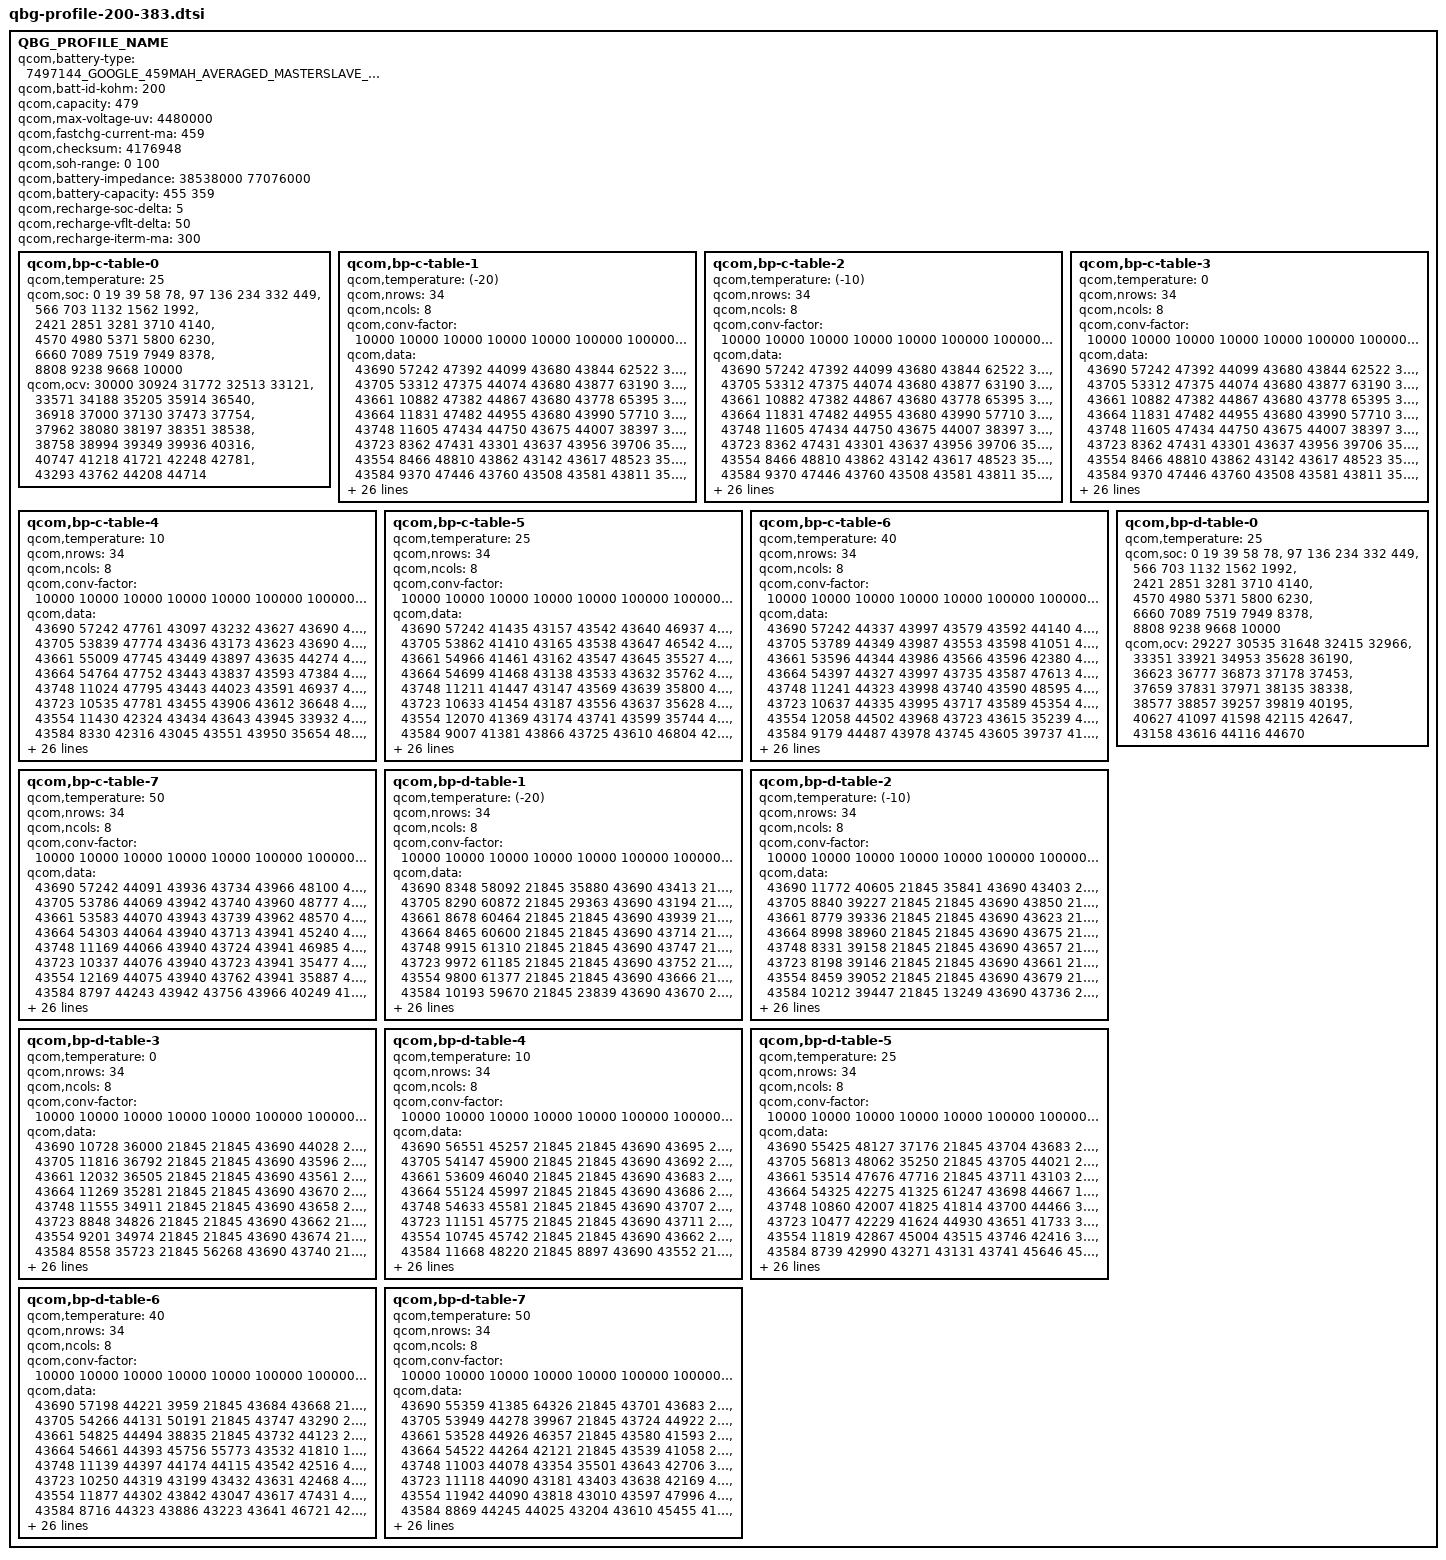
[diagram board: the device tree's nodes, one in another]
/*QBG Profiling Rev. 2.8*/

QBG_PROFILE_NAME {
	qcom,battery-type = "7497144_GOOGLE_459MAH_AVERAGED_MASTERSLAVE_DEC2ND2024";
	qcom,batt-id-kohm = <200>;
	qcom,capacity = <479>;
	qcom,max-voltage-uv = <4480000>;
	qcom,fastchg-current-ma = <459>;
	qcom,checksum = <4176948>; /*@5, 0.005V, 4% */
	qcom,soh-range = <0 100>;
	qcom,battery-impedance = <38538000 77076000>; /*Nominal_Impedance in 10nohm @ SOC 50% 25C* 0:fresh cell, 1: aged cell*/
	qcom,battery-capacity = <455 359>; /*Nominal_Capacity in mAh. 0: fresh cell, 1:aged cell*/
	qcom,recharge-soc-delta =<5>; /*SOC delta (in percent) dropped from EOC SOC to enable recharge*/
	qcom,recharge-vflt-delta =<50>; /*vfloat delta (in mV) dropped from regular vfloat in recharge*/
	qcom,recharge-iterm-ma = <300>; /*termination current (in mA) in recharge*/

	qcom,bp-c-table-0 {
		qcom,temperature = <25>;
		qcom,soc = <    0    19    39    58    78>,
			<   97   136   234   332   449>,
			<  566   703  1132  1562  1992>,
			< 2421  2851  3281  3710  4140>,
			< 4570  4980  5371  5800  6230>,
			< 6660  7089  7519  7949  8378>,
			< 8808  9238  9668 10000>;
		qcom,ocv = <30000 30924 31772 32513 33121>,
			<33571 34188 35205 35914 36540>,
			<36918 37000 37130 37473 37754>,
			<37962 38080 38197 38351 38538>,
			<38758 38994 39349 39936 40316>,
			<40747 41218 41721 42248 42781>,
			<43293 43762 44208 44714>;
	};
	qcom,bp-c-table-1 {
		qcom,temperature = <(-20)>;
		qcom,nrows = <34>;
		qcom,ncols = <8>;
		qcom,conv-factor = <10000 10000 10000 10000 10000 100000 100000 10000>;
		qcom,data = <43690 57242 47392 44099 43680 43844 62522 35052>,
			<43705 53312 47375 44074 43680 43877 63190 34980>,
			<43661 10882 47382 44867 43680 43778 65395 35705>,
			<43664 11831 47482 44955 43680 43990 57710 35634>,
			<43748 11605 47434 44750 43675 44007 38397 35831>,
			<43723  8362 47431 43301 43637 43956 39706 35721>,
			<43554  8466 48810 43862 43142 43617 48523 35347>,
			<43584  9370 47446 43760 43508 43581 43811 35513>,
			<44006  9599 47478 43653 43510 43538 43969 46338>,
			<43883 14906 47480 43679 43415 43536 43997 46480>,
			<43164 14957 47389 43669 43499 43539 43984 46517>,
			<43029 14932 47462 43653 43412 43543 43818 46521>,
			<44742 14514 47470 43558 43469 43538 43799 46539>,
			<44208 14840 48810 44821 43941 43640 33210 34988>,
			<44386 16112 47470 44255 44031 43628 36693 35012>,
			<41951 15937 47570 44115 43800 43626 35830 34878>,
			<41353 16356 47569 44439 43843 43542 46591 35239>,
			<42619 16157 47417 44346 43148 43548 46959 35187>,
			<42196 15507 47486 44382 43204 43525 47082 36470>,
			<47750 15432 48825 41724 43063 43523 46945 36724>,
			<47984 15730 48873 41527 43016 43534 46951 35871>,
			<47582 13190 48667 41570 43216 43574 48158 36315>,
			<48721 12335 49053 41898 43049 43583 48003 33493>,
			<48130 13999 48993 41975 43026 43558 42968 32951>,
			<45820 14130 48345 41852 43439 43566 41432 34493>,
			<45230 13805 48548 41089 43473 43732 41924 33938>,
			<45339  3000 48409 41180 44691 43728 44341 39449>,
			<47093  2143 45596 40988 45003 43731 44261 40612>,
			<46503  3673 45831 40991 44542 43729 44648 37624>,
			<35344  3153 45065 41084 41115 43733 43343 38050>,
			<35010   597 45420 41028 41995 43563 43444 60587>,
			<36540   122 46792 41062 48595 43560 43068 63888>,
			<36718  1536 46691 41186 45332 43579 43178 63108>,
			<36282  1213 46216 43569 45746 43675 43529 65049>;
	};
	qcom,bp-c-table-2 {
		qcom,temperature = <(-10)>;
		qcom,nrows = <34>;
		qcom,ncols = <8>;
		qcom,conv-factor = <10000 10000 10000 10000 10000 100000 100000 10000>;
		qcom,data = <43690 57242 47392 44099 43680 43844 62522 35052>,
			<43705 53312 47375 44074 43680 43877 63190 34980>,
			<43661 10882 47382 44867 43680 43778 65395 35705>,
			<43664 11831 47482 44955 43680 43990 57710 35634>,
			<43748 11605 47434 44750 43675 44007 38397 35831>,
			<43723  8362 47431 43301 43637 43956 39706 35721>,
			<43554  8466 48810 43862 43142 43617 48523 35347>,
			<43584  9370 47446 43760 43508 43581 43811 35513>,
			<44006  9599 47478 43653 43510 43538 43969 46338>,
			<43883 14906 47480 43679 43415 43536 43997 46480>,
			<43164 14957 47389 43669 43499 43539 43984 46517>,
			<43029 14932 47462 43653 43412 43543 43818 46521>,
			<44742 14514 47470 43558 43469 43538 43799 46539>,
			<44208 14840 48810 44821 43941 43640 33210 34988>,
			<44386 16112 47470 44255 44031 43628 36693 35012>,
			<41951 15937 47570 44115 43800 43626 35830 34878>,
			<41353 16356 47569 44439 43843 43542 46591 35239>,
			<42619 16157 47417 44346 43148 43548 46959 35187>,
			<42196 15507 47486 44382 43204 43525 47082 36470>,
			<47750 15432 48825 41724 43063 43523 46945 36724>,
			<47984 15730 48873 41527 43016 43534 46951 35871>,
			<47582 13190 48667 41570 43216 43574 48158 36315>,
			<48721 12335 49053 41898 43049 43583 48003 33493>,
			<48130 13999 48993 41975 43026 43558 42968 32951>,
			<45820 14130 48345 41852 43439 43566 41432 34493>,
			<45230 13805 48548 41089 43473 43732 41924 33938>,
			<45339  3000 48409 41180 44691 43728 44341 39449>,
			<47093  2143 45596 40988 45003 43731 44261 40612>,
			<46503  3673 45831 40991 44542 43729 44648 37624>,
			<35344  3153 45065 41084 41115 43733 43343 38050>,
			<35010   597 45420 41028 41995 43563 43444 60587>,
			<36540   122 46792 41062 48595 43560 43068 63888>,
			<36718  1536 46691 41186 45332 43579 43178 63108>,
			<36282  1213 46216 43569 45746 43675 43529 65049>;
	};
	qcom,bp-c-table-3 {
		qcom,temperature = <0>;
		qcom,nrows = <34>;
		qcom,ncols = <8>;
		qcom,conv-factor = <10000 10000 10000 10000 10000 100000 100000 10000>;
		qcom,data = <43690 57242 47392 44099 43680 43844 62522 35052>,
			<43705 53312 47375 44074 43680 43877 63190 34980>,
			<43661 10882 47382 44867 43680 43778 65395 35705>,
			<43664 11831 47482 44955 43680 43990 57710 35634>,
			<43748 11605 47434 44750 43675 44007 38397 35831>,
			<43723  8362 47431 43301 43637 43956 39706 35721>,
			<43554  8466 48810 43862 43142 43617 48523 35347>,
			<43584  9370 47446 43760 43508 43581 43811 35513>,
			<44006  9599 47478 43653 43510 43538 43969 46338>,
			<43883 14906 47480 43679 43415 43536 43997 46480>,
			<43164 14957 47389 43669 43499 43539 43984 46517>,
			<43029 14932 47462 43653 43412 43543 43818 46521>,
			<44742 14514 47470 43558 43469 43538 43799 46539>,
			<44208 14840 48810 44821 43941 43640 33210 34988>,
			<44386 16112 47470 44255 44031 43628 36693 35012>,
			<41951 15937 47570 44115 43800 43626 35830 34878>,
			<41353 16356 47569 44439 43843 43542 46591 35239>,
			<42619 16157 47417 44346 43148 43548 46959 35187>,
			<42196 15507 47486 44382 43204 43525 47082 36470>,
			<47750 15432 48825 41724 43063 43523 46945 36724>,
			<47984 15730 48873 41527 43016 43534 46951 35871>,
			<47582 13190 48667 41570 43216 43574 48158 36315>,
			<48721 12335 49053 41898 43049 43583 48003 33493>,
			<48130 13999 48993 41975 43026 43558 42968 32951>,
			<45820 14130 48345 41852 43439 43566 41432 34493>,
			<45230 13805 48548 41089 43473 43732 41924 33938>,
			<45339  3000 48409 41180 44691 43728 44341 39449>,
			<47093  2143 45596 40988 45003 43731 44261 40612>,
			<46503  3673 45831 40991 44542 43729 44648 37624>,
			<35344  3153 45065 41084 41115 43733 43343 38050>,
			<35010   597 45420 41028 41995 43563 43444 60587>,
			<36540   122 46792 41062 48595 43560 43068 63888>,
			<36718  1536 46691 41186 45332 43579 43178 63108>,
			<36282  1213 46216 43569 45746 43675 43529 65049>;
	};
	qcom,bp-c-table-4 {
		qcom,temperature = <10>;
		qcom,nrows = <34>;
		qcom,ncols = <8>;
		qcom,conv-factor = <10000 10000 10000 10000 10000 100000 100000 10000>;
		qcom,data = <43690 57242 47761 43097 43232 43627 43690 45102>,
			<43705 53839 47774 43436 43173 43623 43690 45185>,
			<43661 55009 47745 43449 43897 43635 44274 45944>,
			<43664 54764 47752 43443 43837 43593 47384 46035>,
			<43748 11024 47795 43443 44023 43591 46937 45963>,
			<43723 10535 47781 43455 43906 43612 36648 45671>,
			<43554 11430 42324 43434 43643 43945 33932 45721>,
			<43584  8330 42316 43045 43551 43950 35654 48540>,
			<44006  9798 42363 43196 43602 43605 41573 48158>,
			<43883  9719 42271 43576 43241 43979 43112 48361>,
			<43164 15068 42297 43747 43044 43821 43991 48979>,
			<43029 14876 42278 43669 43062 43812 43996 49019>,
			<44742 15359 42445 43096 43577 43943 33431 48354>,
			<44208 14353 42424 44770 43595 43616 36732 48539>,
			<44386 14713 42093 44598 43957 43630 35969 48529>,
			<41951 15926 42192 44659 43921 43541 35311 48566>,
			<41353 16299 42216 44633 44031 43540 35627 48568>,
			<42619 16324 42151 44967 43993 43537 46288 48559>,
			<42196 16223 42147 44979 43813 43536 45368 48573>,
			<47750 15410 42843 44934 43801 43539 46639 48541>,
			<47984 15867 42826 45054 43903 43536 36316 48578>,
			<47582 12841 42865 45049 43777 43537 32848 48542>,
			<48721 12532 42878 44929 43922 43539 47036 48188>,
			<48130 13997 42825 45042 43924 43546 48859 48244>,
			<45820 14128 42123 44816 43999 43529 48055 48506>,
			<45230 13793 42194 44212 43780 43570 42021 45634>,
			<45339  2996 42098 44242 43179 43578 42666 45193>,
			<47093  2491 42495 44135 43048 43553 41736 45328>,
			<46503  4017 42353 44464 43490 43552 44399 46854>,
			<35344  3460 47814 44533 44584 43553 44284 35472>,
			<35010   926 48063 44508 44035 43557 44608 35145>,
			<36540   419 47901 44493 41455 43580 43370 32910>,
			<36718  1632 47259 44885 42827 43545 43468 34797>,
			<36282  1245 47224 43083 47789 43566 43913 33877>;
	};
	qcom,bp-c-table-5 {
		qcom,temperature = <25>;
		qcom,nrows = <34>;
		qcom,ncols = <8>;
		qcom,conv-factor = <10000 10000 10000 10000 10000 100000 100000 10000>;
		qcom,data = <43690 57242 41435 43157 43542 43640 46937 47762>,
			<43705 53862 41410 43165 43538 43647 46542 47781>,
			<43661 54966 41461 43162 43547 43645 35527 42318>,
			<43664 54699 41468 43138 43533 43632 35762 42256>,
			<43748 11211 41447 43147 43569 43639 35800 42277>,
			<43723 10633 41454 43187 43556 43637 35628 42444>,
			<43554 12070 41369 43174 43741 43599 35744 42422>,
			<43584  9007 41381 43866 43725 43610 46804 42008>,
			<44006  9952 41031 43893 43724 43603 45576 42201>,
			<43883  9238 41087 43888 43724 43607 48398 42219>,
			<43164 15004 41065 43872 43770 43945 46485 42158>,
			<43029 14882 40986 43605 43956 44006 42075 42818>,
			<44742 15264 41021 43140 43557 43584 46019 42187>,
			<44208 14539 41202 43025 43641 43625 45226 42076>,
			<44386 14800 41090 43086 43605 43625 45472 42431>,
			<41951 16096 41821 43439 43947 43626 46581 42410>,
			<41353 15978 41830 43427 43945 43626 46398 42105>,
			<42619 16287 41753 43450 43936 43626 45500 42088>,
			<42196 16229 41789 43093 43931 43540 47153 42007>,
			<47750 15392 41771 43082 43986 43543 42788 42087>,
			<47984 15820 41926 43080 43803 43549 42195 42049>,
			<47582 13048 41983 43440 43803 43542 46101 42406>,
			<48721 13087 41960 43397 43974 43625 36053 42108>,
			<48130 13994 41886 43124 43600 43536 42192 42844>,
			<45820 14294 41870 43100 43941 43551 42888 42174>,
			<45230 13697 41866 43448 43914 43546 41223 42222>,
			<45339  2984 41867 43396 43922 43526 41207 42199>,
			<47093  2131 41869 43476 43995 43535 41561 42429>,
			<46503  4002 41983 43283 43903 43530 44530 42329>,
			<35344  3511 41774 43347 43256 43531 44153 47693>,
			<35010   951 41756 44722 43400 43532 44214 47285>,
			<36540    88 41821 44672 44933 43525 44619 48653>,
			<36718  1562 41167 43505 43274 43550 44310 47133>,
			<36282  1024 40977 43875 42527 43526 43973 45173>;
	};
	qcom,bp-c-table-6 {
		qcom,temperature = <40>;
		qcom,nrows = <34>;
		qcom,ncols = <8>;
		qcom,conv-factor = <10000 10000 10000 10000 10000 100000 100000 10000>;
		qcom,data = <43690 57242 44337 43997 43579 43592 44140 41110>,
			<43705 53789 44349 43987 43553 43598 41051 41093>,
			<43661 53596 44344 43986 43566 43596 42380 41098>,
			<43664 54397 44327 43997 43735 43587 47613 41147>,
			<43748 11241 44323 43998 43740 43590 48595 41130>,
			<43723 10637 44335 43995 43717 43589 45354 41797>,
			<43554 12058 44502 43968 43723 43615 35239 41829>,
			<43584  9179 44487 43978 43745 43605 39737 41778>,
			<44006  9864 44494 44018 43756 43948 39522 41943>,
			<43883  9248 44529 44015 43744 43962 46239 41935>,
			<43164 15039 44542 43958 43770 43954 48236 41872>,
			<43029 15041 44512 43959 43752 43964 46202 41871>,
			<44742 14975 44523 43921 43553 43962 47795 41763>,
			<44208 14473 44440 43986 43540 43608 47678 41820>,
			<44386 14750 44431 43839 43636 43588 47216 41090>,
			<41951 16046 44476 43784 43638 43587 45975 41091>,
			<41353 15925 44463 43824 43626 43587 48413 41822>,
			<42619 16270 44120 43780 43541 43593 49010 41808>,
			<42196 16227 44111 43881 43647 43597 47771 41136>,
			<47750 15422 44146 43978 43981 43612 44426 41194>,
			<47984 15825 44135 44003 43799 43611 44246 41153>,
			<47582 12842 44142 43999 43781 43597 42674 41168>,
			<48721 13151 44052 43839 44010 43596 42457 41194>,
			<48130 13986 44051 43822 43628 43585 41233 41736>,
			<45820 14138 44057 43823 43635 43584 41920 41755>,
			<45230 13804 44037 43784 43597 43592 41590 41845>,
			<45339  2997 44059 43875 43602 43635 41493 41140>,
			<47093  2481 44062 43842 43954 43641 44367 41154>,
			<46503  3969 44049 43186 44014 43629 44467 41087>,
			<35344  3473 44143 43253 43810 43627 44424 41408>,
			<35010   922 44156 43231 43863 43625 44053 42663>,
			<36540    87 44097 43230 43100 43619 44803 42940>,
			<36718  1643 44455 43879 43886 43638 41657 41446>,
			<36282  1132 44422 43929 44422 43934 43778 47863>;
	};
	qcom,bp-c-table-7 {
		qcom,temperature = <50>;
		qcom,nrows = <34>;
		qcom,ncols = <8>;
		qcom,conv-factor = <10000 10000 10000 10000 10000 100000 100000 10000>;
		qcom,data = <43690 57242 44091 43936 43734 43966 48100 41512>,
			<43705 53786 44069 43942 43740 43960 48777 41686>,
			<43661 53583 44070 43943 43739 43962 48570 41693>,
			<43664 54303 44064 43940 43713 43941 45240 41688>,
			<43748 11169 44066 43940 43724 43941 46985 41670>,
			<43723 10337 44076 43940 43723 43941 35477 41677>,
			<43554 12169 44075 43940 43762 43941 35887 41713>,
			<43584  8797 44243 43942 43756 43966 40249 41620>,
			<44006  8475 44249 43949 43670 43958 37633 41612>,
			<43883  9393 44228 43944 43664 43913 39752 41651>,
			<43164  9580 44225 43639 43669 43925 46486 44379>,
			<43029 15007 44236 43624 43668 44011 45452 44411>,
			<44742 14910 44235 43611 43554 43934 42235 41722>,
			<44208 15218 44278 43958 43568 43915 47330 41530>,
			<44386 14430 44285 43965 43620 43912 42108 41501>,
			<41951 14690 44261 43960 43593 43956 47650 41577>,
			<41353 15915 44271 43941 43520 43955 47121 41684>,
			<42619 16316 44176 43916 43534 43942 47127 41510>,
			<42196 16234 44185 44027 43550 43948 42491 41577>,
			<47750 15399 44161 43905 43967 43918 44389 41565>,
			<47984 15830 44169 43621 43790 43908 45033 41911>,
			<47582 12833 44215 43596 43829 43915 41508 41909>,
			<48721 12461 44211 43951 43915 43952 41259 41599>,
			<48130 13987 44220 43950 43523 43956 41388 41702>,
			<45820 14142 44217 43963 43525 43965 41778 41717>,
			<45230 13796 44216 43907 43630 43942 41514 41531>,
			<45339  2948 44216 44010 43593 43945 44510 41572>,
			<47093  2433 44222 43978 43604 43603 44469 41914>,
			<46503  3996 44210 43839 43948 43588 41713 41983>,
			<35344  3567 44209 43883 43924 43595 44498 41827>,
			<35010   926 44171 43845 43835 43592 44321 41191>,
			<36540    82 44161 43871 43136 43586 44431 41049>,
			<36718  1644 44183 44022 44001 43944 41900 41939>,
			<36282  1146 44256 43599 44425 43822 43835 42413>;
	};
	qcom,bp-d-table-0 {
		qcom,temperature = <25>;
		qcom,soc = <    0    19    39    58    78>,
			<   97   136   234   332   449>,
			<  566   703  1132  1562  1992>,
			< 2421  2851  3281  3710  4140>,
			< 4570  4980  5371  5800  6230>,
			< 6660  7089  7519  7949  8378>,
			< 8808  9238  9668 10000>;
		qcom,ocv = <29227 30535 31648 32415 32966>,
			<33351 33921 34953 35628 36190>,
			<36623 36777 36873 37178 37453>,
			<37659 37831 37971 38135 38338>,
			<38577 38857 39257 39819 40195>,
			<40627 41097 41598 42115 42647>,
			<43158 43616 44116 44670>;
	};
	qcom,bp-d-table-1 {
		qcom,temperature = <(-20)>;
		qcom,nrows = <34>;
		qcom,ncols = <8>;
		qcom,conv-factor = <10000 10000 10000 10000 10000 100000 100000 10000>;
		qcom,data = <43690  8348 58092 21845 35880 43690 43413 21845>,
			<43705  8290 60872 21845 29363 43690 43194 21845>,
			<43661  8678 60464 21845 21845 43690 43939 21845>,
			<43664  8465 60600 21845 21845 43690 43714 21845>,
			<43748  9915 61310 21845 21845 43690 43747 21845>,
			<43723  9972 61185 21845 21845 43690 43752 21845>,
			<43554  9800 61377 21845 21845 43690 43666 21845>,
			<43584 10193 59670 21845 23839 43690 43670 21845>,
			<44006 10072 60255 21845 54731 43690 43723 21845>,
			<43883  9438 59917 21845 58122 43690 43535 21845>,
			<43164  9332 37937 21845 39846 43690 43588 21845>,
			<43029  9696 38570 21845 35262 43690 43927 21845>,
			<44742 15098 40402  3547 45687 43691 43191 21845>,
			<44208 15290 40125 53903 48473 43691 43220 21845>,
			<44386 15120 38971 62122 47514 43688 43132 21845>,
			<41951 14538 34171 60239 42097 43689 43493 17606>,
			<41353 14760 34758 39147 41314 43689 43288 25435>,
			<42619 14607 33072 36304 41849 43694 43332  1419>,
			<42196 16123 33610 46438 41512 43694 44679 12509>,
			<47750 16288 36193 45916 44344 43695 44579  9000>,
			<47984 16231 36072 48937 44109 43693 44642 53623>,
			<47582 15411 36443 47138 44180 43682 45026 56212>,
			<48721 15824 35105 47651 45054 43680 44036 52570>,
			<48130 12905 34928 42341 44974 43686 41817 51264>,
			<45820 12490 34824 42454 45010 43687 41271 52042>,
			<45230 14061 34865 42423 44255 43702 42580 51411>,
			<45339 13525 34820 42011 44458 43763 47307 51534>,
			<47093  2661 35062 42121 44306 43569 48689 53127>,
			<46503  2115 35049 42409 41654 43581 47527 52415>,
			<35344  4026 35043 42335 41674 43556 47992 52304>,
			<35010  3474 35000 47704 41683 43563 42354 49839>,
			<36540   993 35665 47904 41609 43717 42746 49880>,
			<36718   357 35065 47873 44089 43775 44146 49874>,
			<36282  1025 34891 48030 44922 43669 43174 49815>;
	};
	qcom,bp-d-table-2 {
		qcom,temperature = <(-10)>;
		qcom,nrows = <34>;
		qcom,ncols = <8>;
		qcom,conv-factor = <10000 10000 10000 10000 10000 100000 100000 10000>;
		qcom,data = <43690 11772 40605 21845 35841 43690 43403 21845>,
			<43705  8840 39227 21845 21845 43690 43850 21845>,
			<43661  8779 39336 21845 21845 43690 43623 21845>,
			<43664  8998 38960 21845 21845 43690 43675 21845>,
			<43748  8331 39158 21845 21845 43690 43657 21845>,
			<43723  8198 39146 21845 21845 43690 43661 21845>,
			<43554  8459 39052 21845 21845 43690 43679 21845>,
			<43584 10212 39447 21845 13249 43690 43736 21845>,
			<44006  9453 34303 21845 38393 43690 43591 21845>,
			<43883  9281 34363 21845 47058 43690 43777 21845>,
			<43164  9701 33004   659 48086 43691 43159 21845>,
			<43029  9500 33443 63103 41416 43691 43396 21845>,
			<44742 14955 35305 35575 44184 43689 44991 15488>,
			<44208 15317 46400 45224 44157 43695 44872 53309>,
			<44386 14515 47093 47146 44612 43693 44477 51779>,
			<41951 14341 46803 42205 44711 43680 44490 65246>,
			<41353 14816 46751 42523 43278 43686 44392 58629>,
			<42619 14659 46734 41445 43509 43704 41696 59317>,
			<42196 15910 46744 41094 43408 43697 41694 57413>,
			<47750 16277 46731 41205 43415 43710 41690 58158>,
			<47984 15525 46825 41952 43420 43703 41573 58003>,
			<47582 15810 46734 41589 43416 43555 45461 58076>,
			<48721 12910 46778 41584 43365 43574 45919 57863>,
			<48130 12529 46765 41903 44667 43534 48663 58303>,
			<45820 13954 45397 41781 44855 43523 47177 58220>,
			<45230 13446 45377 41173 44233 43523 47247 57406>,
			<45339  2717 45420 41437 44100 43575 47657 57835>,
			<47093  2286 45385 42557 44471 43576 47796 59108>,
			<46503  3821 45335 42945 44527 43563 42094 58987>,
			<35344  3302 45368 42129 44494 43743 42867 59145>,
			<35010   657 45532 42077 44489 43719 42741 58421>,
			<36540   163 45529 42433 44097 43723 41110 58483>,
			<36718  1692 45327 42277 44968 43770 44398 58404>,
			<36282  1040 45415 42467 44728 43755 44813 59256>;
	};
	qcom,bp-d-table-3 {
		qcom,temperature = <0>;
		qcom,nrows = <34>;
		qcom,ncols = <8>;
		qcom,conv-factor = <10000 10000 10000 10000 10000 100000 100000 10000>;
		qcom,data = <43690 10728 36000 21845 21845 43690 44028 21845>,
			<43705 11816 36792 21845 21845 43690 43596 21845>,
			<43661 12032 36505 21845 21845 43690 43561 21845>,
			<43664 11269 35281 21845 21845 43690 43670 21845>,
			<43748 11555 34911 21845 21845 43690 43658 21845>,
			<43723  8848 34826 21845 21845 43690 43662 21845>,
			<43554  9201 34974 21845 21845 43690 43674 21845>,
			<43584  8558 35723 21845 56268 43690 43740 21845>,
			<44006 10009 46367 21845 34882 43690 43924 21845>,
			<43883  9332 46975 11338 42194 43691 43056 21845>,
			<43164  9700 46820 37731 44334 43691 43351 28134>,
			<43029  9533 45459 46784 44580 43688 44956  8849>,
			<44742 15044 45807 41195 43064 43693 41661 58951>,
			<44208 15303 48550 40963 43024 43680 40970 61255>,
			<44386 14585 48178 41939 43088 43706 42570 60134>,
			<41951 14416 48160 44388 43088 43703 41290 38587>,
			<41353 14637 48365 44067 43023 43746 41439 37498>,
			<42619 16033 48381 44918 43137 43558 42681 40131>,
			<42196 15920 48342 44812 43863 43582 41393 40488>,
			<47750 16328 48369 44872 43879 43574 47136 39345>,
			<47984 15375 48328 44214 43021 43534 45189 39421>,
			<47582 15713 48331 44215 43506 43522 47608 39321>,
			<48721 13241 48373 44272 43340 43525 42365 39423>,
			<48130 12411 48370 44435 44580 43545 42257 40634>,
			<45820 13920 48361 41697 45050 43521 47777 40890>,
			<45230 13409 48256 41886 44891 43568 42156 40818>,
			<45339  2588 48303 41822 44213 43552 41236 40113>,
			<47093  2051 48293 40993 44171 43730 41098 40161>,
			<46503  3584 49011 41405 44200 43716 41733 39975>,
			<35344  3102 49003 41269 44883 43715 41811 40383>,
			<35010   520 48901 41289 44869 43726 41776 40403>,
			<36540   202 48900 42662 45014 43764 41961 40403>,
			<36718  1742 48993 42652 43293 43769 41969 40027>,
			<36282  1055 48990 42750 43112 43744 41777 40169>;
	};
	qcom,bp-d-table-4 {
		qcom,temperature = <10>;
		qcom,nrows = <34>;
		qcom,ncols = <8>;
		qcom,conv-factor = <10000 10000 10000 10000 10000 100000 100000 10000>;
		qcom,data = <43690 56551 45257 21845 21845 43690 43695 21845>,
			<43705 54147 45900 21845 21845 43690 43692 21845>,
			<43661 53609 46040 21845 21845 43690 43683 21845>,
			<43664 55124 45997 21845 21845 43690 43686 21845>,
			<43748 54633 45581 21845 21845 43690 43707 21845>,
			<43723 11151 45775 21845 21845 43690 43711 21845>,
			<43554 10745 45742 21845 21845 43690 43662 21845>,
			<43584 11668 48220 21845  8897 43690 43552 21845>,
			<44006  8328 49012  1774 45349 43690 43888 21845>,
			<43883  9828 48693 34424 44541 43691 44673   387>,
			<43164  9242 47396 47748 44675 43689 44446 52224>,
			<43029  9717 47152 41578 43227 43683 41000 59440>,
			<44742  9563 47343 44743 43985 43745 41221 34404>,
			<44208 15237 47874 44586 43868 43719 42940 33785>,
			<44386 14538 48003 44582 43200 43573 48119 35983>,
			<41951 14774 48056 44762 43218 43520 47684 35134>,
			<41353 14628 48062 44700 43862 43546 42284 35822>,
			<42619 16034 47700 44682 43824 43550 47647 46339>,
			<42196 15993 47705 44768 43887 43538 46841 46471>,
			<47750 16140 47702 44685 43146 43538 49142 46106>,
			<47984 15410 47685 44675 43213 43542 42045 46307>,
			<47582 15639 47716 44737 43063 43540 42174 46236>,
			<48721 13239 47628 44612 43076 43537 42049 46278>,
			<48130 12714 47659 44860 43283 43551 42356 46377>,
			<45820 14220 47839 44262 44557 43545 48025 35417>,
			<45230 13376 47818 44231 44658 43572 41376 35712>,
			<45339  2667 47847 44068 44654 43556 41712 35810>,
			<47093  2066 47863 44151 44741 43555 41698 35631>,
			<46503  3692 47858 44438 44679 43564 41562 35667>,
			<35344  3198 47869 44526 44691 43562 41563 35023>,
			<35010   611 47861 44520 44694 43735 41561 34844>,
			<36540    35 47826 44436 43356 43729 41872 34916>,
			<36718  1756 47641 44427 43099 43740 41781 34919>,
			<36282  1025 47733 44452 43262 43737 41795 34915>;
	};
	qcom,bp-d-table-5 {
		qcom,temperature = <25>;
		qcom,nrows = <34>;
		qcom,ncols = <8>;
		qcom,conv-factor = <10000 10000 10000 10000 10000 100000 100000 10000>;
		qcom,data = <43690 55425 48127 37176 21845 43704 43683 21845>,
			<43705 56813 48062 35250 21845 43705 44021 21845>,
			<43661 53514 47676 47716 21845 43711 43103 21845>,
			<43664 54325 42275 41325 61247 43698 44667 11100>,
			<43748 10860 42007 41825 41814 43700 44466 38003>,
			<43723 10477 42229 41624 44930 43651 41733 39727>,
			<43554 11819 42867 45004 43515 43746 42416 36790>,
			<43584  8739 42990 43271 43131 43741 45646 45312>,
			<44006  8582 42576 43486 43048 43567 46651 45989>,
			<43883 10228 42544 43427 43810 43577 48293 49014>,
			<43164  9637 42708 43100 43985 43568 42568 48649>,
			<43029  9475 42654 43114 43978 43528 42652 47392>,
			<44742 15011 41318 43238 43551 43536 48682 48045>,
			<44208 15248 41434 43204 43927 43538 42615 48024>,
			<44386 14567 41406 43226 43990 43626 42911 47635>,
			<41951 14769 41038 43042 43780 43631 42380 47665>,
			<41353 14701 41065 43063 43877 43617 48793 47653>,
			<42619 16121 40973 43218 43884 43618 42348 47754>,
			<42196 15965 41004 43227 43786 43618 42906 42259>,
			<47750 16232 41200 43055 43998 43629 42225 42432>,
			<47984 15387 41109 43066 43970 43631 42206 42475>,
			<47582 15715 41098 43061 43984 43630 41993 42466>,
			<48721 13299 41813 43078 43144 43617 47346 47783>,
			<48130 12577 41804 43463 43459 43633 45648 47994>,
			<45820 14249 41849 43440 43482 43539 41738 48072>,
			<45230 13337 41836 43395 43098 43548 44502 47703>,
			<45339  2595 41750 43460 43157 43538 41514 47649>,
			<47093  2260 41745 43316 43783 43548 41445 47761>,
			<46503  3625 41854 43464 43778 43527 41795 47781>,
			<35344  3133 41795 43513 43836 43525 41466 47779>,
			<35010   572 41808 43415 43825 43548 41318 47777>,
			<36540   202 41151 43428 43783 43539 41441 47806>,
			<36718  1790 41195 43102 43789 43551 41434 47759>,
			<36282  1236 41154 43076 43815 43527 42676 47774>;
	};
	qcom,bp-d-table-6 {
		qcom,temperature = <40>;
		qcom,nrows = <34>;
		qcom,ncols = <8>;
		qcom,conv-factor = <10000 10000 10000 10000 10000 100000 100000 10000>;
		qcom,data = <43690 57198 44221  3959 21845 43684 43668 21845>,
			<43705 54266 44131 50191 21845 43747 43290 21845>,
			<43661 54825 44494 38835 21845 43732 44123 21845>,
			<43664 54661 44393 45756 55773 43532 41810 15597>,
			<43748 11139 44397 44174 44115 43542 42516 48289>,
			<43723 10250 44319 43199 43432 43631 42468 42784>,
			<43554 11877 44302 43842 43047 43617 47431 42598>,
			<43584  8716 44323 43886 43223 43641 46721 42704>,
			<44006  8590 44496 43805 43238 43634 35420 42632>,
			<43883 10222 44486 43800 44020 43639 35050 41395>,
			<43164  9284 44493 43796 43548 43635 45673 41169>,
			<43029  9494 44491 43893 43546 43635 47314 41020>,
			<44742 15019 44539 43922 43743 43613 49092 41761>,
			<44208 15280 44434 43991 43551 43615 47346 41815>,
			<44386 14513 44426 43970 43632 43607 42069 41796>,
			<41951 14419 44479 43979 43930 43604 42827 41112>,
			<41353 14711 44453 43971 43886 43944 40977 41058>,
			<42619 15917 44457 43814 43785 43605 42624 40983>,
			<42196 16284 44114 43990 43996 43605 41372 41181>,
			<47750 15530 44102 43815 43914 43601 42133 41088>,
			<47984 15437 44104 43996 43946 43602 42975 41801>,
			<47582 12971 44147 43994 43966 43615 42993 41797>,
			<48721 13099 44133 43809 43795 43610 42937 40965>,
			<48130 12603 44141 43892 43031 43608 41801 41308>,
			<45820 14217 44137 43228 43883 43913 41180 41247>,
			<45230 13438 44053 43057 43908 43588 42955 41448>,
			<45339  2566 44138 43210 43951 43623 42505 41076>,
			<47093  2056 44137 43153 43632 43616 42080 41019>,
			<46503  3590 44130 43199 43626 43623 47729 41214>,
			<35344  3089 44135 43840 43541 43647 47700 41103>,
			<35010   537 44156 43880 43631 43637 47838 41132>,
			<36540   209 44107 43830 43638 43584 42081 41813>,
			<36718  1737 44103 43992 43966 43613 41413 41127>,
			<36282  1226 44125 44005 44010 43947 41482 41113>;
	};
	qcom,bp-d-table-7 {
		qcom,temperature = <50>;
		qcom,nrows = <34>;
		qcom,ncols = <8>;
		qcom,conv-factor = <10000 10000 10000 10000 10000 100000 100000 10000>;
		qcom,data = <43690 55359 41385 64326 21845 43701 43683 21845>,
			<43705 53949 44278 39967 21845 43724 44922 21845>,
			<43661 53528 44926 46357 21845 43580 41593 21845>,
			<43664 54522 44264 42121 21845 43539 41058 21845>,
			<43748 11003 44078 43354 35501 43643 42706 33206>,
			<43723 11118 44090 43181 43403 43638 42169 42731>,
			<43554 11942 44090 43818 43010 43597 47996 41454>,
			<43584  8869 44245 44025 43204 43610 45455 41082>,
			<44006  8196 44249 44014 43061 43614 35485 41034>,
			<43883  9834 44227 43926 43832 43601 35708 41747>,
			<43164  9428 44233 44014 43631 43613 35237 41565>,
			<43029  9519 44233 43987 43575 43585 47645 41891>,
			<44742  9584 44272 43637 43726 43916 45800 41662>,
			<44208 14960 44262 43943 43581 43919 47797 41665>,
			<44386 15182 44181 43964 43522 43908 47511 41693>,
			<41951 14441 44177 43604 43585 43935 42112 41522>,
			<41353 14705 44179 43911 43826 43922 41307 41938>,
			<42619 15933 44185 43927 43832 43926 41095 41942>,
			<42196 16365 44164 44026 43933 43922 42700 41883>,
			<47750 15525 44162 43926 43611 43911 42856 41592>,
			<47984 15440 44168 43913 43629 43906 47766 41506>,
			<47582 12991 44214 43956 43634 43906 47770 41528>,
			<48721 13092 44211 43931 43980 43904 42547 41876>,
			<48130 12594 44221 43792 43199 43909 41917 41159>,
			<45820 14220 44223 43148 43917 43967 42655 41133>,
			<45230 13431 44223 43173 43632 43586 42098 41742>,
			<45339  2589 44223 43866 43534 43598 47384 41977>,
			<47093  2054 44221 43788 43520 43596 42103 41889>,
			<46503  3615 44208 43985 43572 43588 42449 41593>,
			<35344  3176 44215 44016 43581 43600 47747 41474>,
			<35010   540 44169 43929 43569 43939 42454 41506>,
			<36540   213 44160 43913 43546 43955 42065 41519>,
			<36718  1728 44190 43912 43645 43919 48009 41501>,
			<36282  1226 44182 43918 43602 43904 48863 41565>;
	};
};
